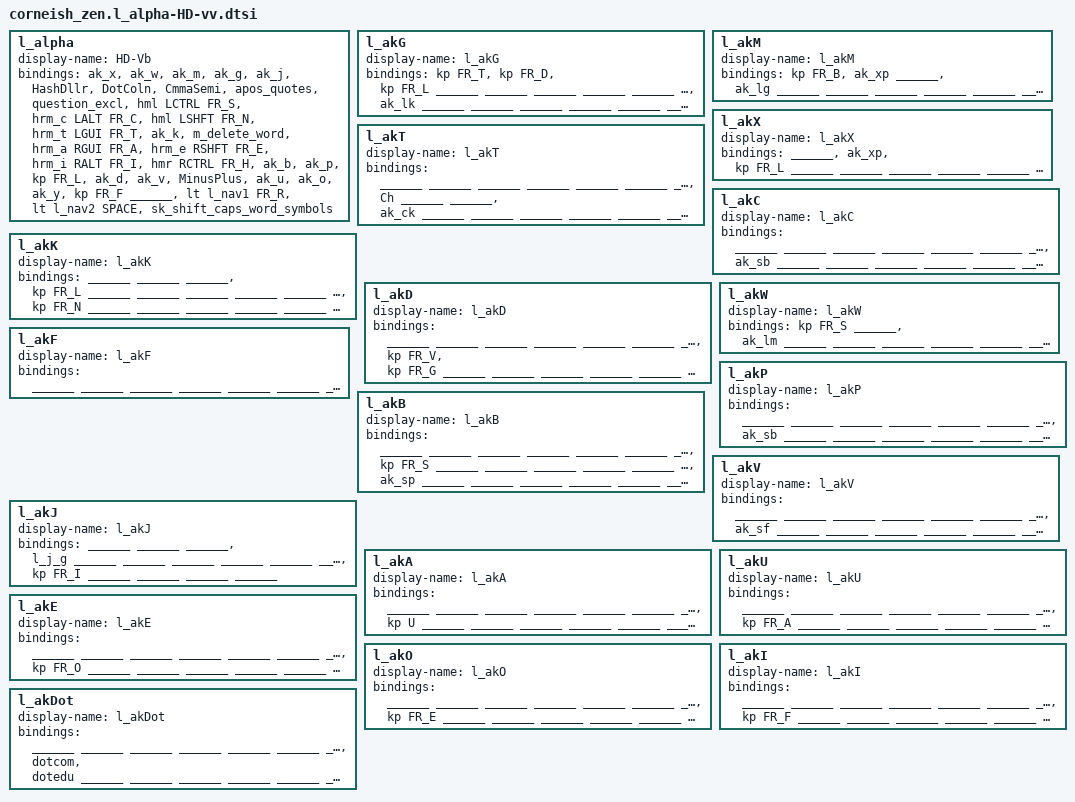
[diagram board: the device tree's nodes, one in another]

/* Base (alpha) Layer	Hands Down Vibranium-Vb
    Building for a 34 key board
*/

l_alpha {
	display-name = "HD-Vb";
	bindings = <
        &ak_x	&ak_w	&ak_m	&ak_g	&ak_j	&HashDllr	&DotColn	&CmmaSemi	&apos_quotes	&question_excl	
        &hml LCTRL FR_S	&hrm_c LALT FR_C	&hml LSHFT FR_N	&hrm_t LGUI FR_T	&ak_k	&m_delete_word	&hrm_a RGUI FR_A	&hrm_e RSHFT FR_E	&hrm_i RALT FR_I	&hmr RCTRL FR_H 
        &ak_b	&ak_p	&kp FR_L	&ak_d	&ak_v	&MinusPlus	&ak_u	&ak_o	&ak_y	&kp FR_F 
                    ______	&lt l_nav1 FR_R	&lt l_nav2 SPACE	&sk_shift_caps_word_symbols
    >;
};

l_akG {
	display-name = "l_akG";
	bindings = <
		&kp FR_T	&kp FR_D	&kp FR_L	______	______	______	______	______	______	______
		______	______	______	______	&ak_lk	______	______	______	______	______
		______	______	______	______	______	______	______	______	______	______
                        ______	______	______	______
	>;
};
l_akM {
	display-name = "l_akM";
	bindings = <
		&kp FR_B	&ak_xp	______	&ak_lg	______	______	______	______	______	______
		______	______	______	______	______	______	______	______	______	______
		______	______	______	______	______	______	______	______	______	______
                        ______	______	______	______
	>;
};
l_akX {
	display-name = "l_akX";
	bindings = <
		______	&ak_xp	&kp FR_L	______	______	______	______	______	______	______
		______	______	______	______	______	______	______	______	______	______
		______	______	______	______	______	______	______	______	______	______
                        ______	______	______	______
	>;
};
l_akT {
	display-name = "l_akT";
	bindings = <
		______	______	______	______	______	______	______	______	______	______
		______	&Ch	______	______	&ak_ck	______	______	______	______	______
		______	______	______	______	______	______	______	______	______	______
                        ______	______	______	______
	>;
};
l_akC {
	display-name = "l_akC";
	bindings = <
		______	______	______	______	______	______	______	______	______	______
		______	______	______	______	______	______	______	______	______	______
		&ak_sb	______	______	______	______	______	______	______	______	______
                        ______	______	______	______
	>;
};
l_akK {
	display-name = "l_akK";
	bindings = <
		______	______	______	&kp FR_L	______	______	______	______	______	______
		______	______	______	&kp FR_N	______	______	______	______	______	______
		______	______	______	______	______	______	______	______	______	______
                        ______	______	______	______
	>;
};
l_akD {
	display-name = "l_akD";
	bindings = <
		______	______	______	______	______	______	______	______	______	______
		______	______	______	______	______	______	______	______	______	______
		&kp FR_V	&kp FR_G	______	______	______	______	______	______	______	______
                        ______	______	______	______
	>;
};
l_akW {
	display-name = "l_akW";
	bindings = <
		&kp FR_S	______	&ak_lm	______	______	______	______	______	______	______
		______	______	______	______	______	______	______	______	______	______
		______	______	______	______	______	______	______	______	______	______
                        ______	______	______	______
	>;
};
l_akF {
	display-name = "l_akF";
	bindings = <
		______	______	______	______	______	______	______	______	______	______
		______	______	______	______	______	______	______	______	______	______
		______	______	______	______	______	______	______	______	______	______
                        ______	______	______	______
	>;
};
l_akP {
	display-name = "l_akP";
	bindings = <
		______	______	______	______	______	______	______	______	______	______
		______	______	______	______	______	______	______	______	______	______
		&ak_sb	______	______	______	______	______	______	______	______	______
                        ______	______	______	______
	>;
};
l_akB {
	display-name = "l_akB";
	bindings = <
		______	______	______	______	______	______	______	______	______	______
		______	&kp FR_S	______	______	______	______	______	______	______	______
		______	&ak_sp	______	______	______	______	______	______	______	______
                        ______	______	______	______
	>;
};
l_akV {
	display-name = "l_akV";
	bindings = <
		______	______	______	______	______	______	______	______	______	______
		______	______	______	______	______	______	______	______	______	______
		______	&ak_sf	______	______	______	______	______	______	______	______
                        ______	______	______	______
	>;
};
l_akJ {
	display-name = "l_akJ";
	bindings = <
		______	______	______	&l_j_g	______	______	______	______	______	______
		______	______	______	______	______	______	______	______	______	______
		______	______	______	______	______	______	______	______	______	&kp FR_I 
                        ______	______	______	______
	>;
};

l_akA {
	display-name = "l_akA";
	bindings = <
		______	______	______	______	______	______	______	______	______	______
		______	______	______	______	______	______	______	______	______	&kp U
		______	______	______	______	______	______	______	______	______	______
                        ______	______	______	______
	>;
};
l_akU {
	display-name = "l_akU";
	bindings = <
		______	______	______	______	______	______	______	______	______	______
		______	______	______	______	______	______	______	______	______	&kp FR_A 
		______	______	______	______	______	______	______	______	______	______
                        ______	______	______	______
	>;
};
l_akE {
	display-name = "l_akE";
	bindings = <
		______	______	______	______	______	______	______	______	______	______
		______	______	______	______	______	______	______	______	______	&kp FR_O 
		______	______	______	______	______	______	______	______	______	______
                        ______	______	______	______
	>;
};
l_akO {
	display-name = "l_akO";
	bindings = <
		______	______	______	______	______	______	______	______	______	______
		______	______	______	______	______	______	______	______	______	&kp FR_E 
		______	______	______	______	______	______	______	______	______	______
                        ______	______	______	______
	>;
};
l_akI {
	display-name = "l_akI";
	bindings = <
		______	______	______	______	______	______	______	______	______	______
		______	______	______	______	______	______	______	______	______	&kp FR_F 
		______	______	______	______	______	______	______	______	______	______
                        ______	______	______	______
	>;
};

l_akDot {
	display-name = "l_akDot";
	bindings = <
		______	______	______	______	______	______	______	&dotcom &dotedu ______
		______	______	______	______	______	______	______	______	______	______
		______	______	______	______	______	______	______	______	______	______
                        ______	______	______	______
	>;
};
